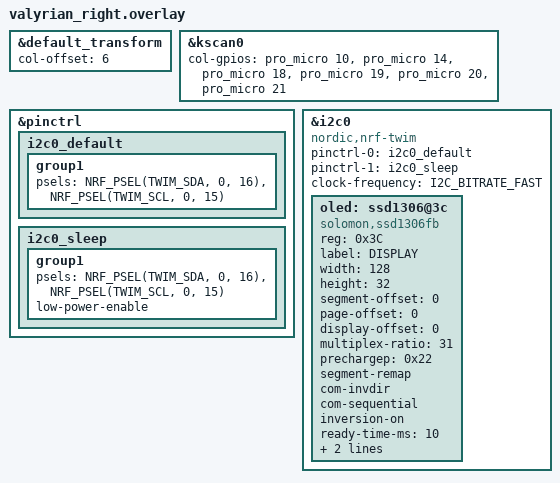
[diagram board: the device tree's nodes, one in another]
#include "valyrian.dtsi" 

&default_transform {
    col-offset = <6>;
};

&kscan0 {
    col-gpios
        = <&pro_micro 10 GPIO_ACTIVE_HIGH>
        , <&pro_micro 14 GPIO_ACTIVE_HIGH>
        , <&pro_micro 18 GPIO_ACTIVE_HIGH>
        , <&pro_micro 19 GPIO_ACTIVE_HIGH>
        , <&pro_micro 20 GPIO_ACTIVE_HIGH>
        , <&pro_micro 21 GPIO_ACTIVE_HIGH>
        ;
};

&pinctrl {
    /* configuration for i2c0 device, default state */
    i2c0_default: i2c0_default {
        group1 {
            psels = <NRF_PSEL(TWIM_SDA, 0, 16)>,
                <NRF_PSEL(TWIM_SCL, 0, 15)>;
        };
    };

    i2c0_sleep: i2c0_sleep {
        group1 {
            psels = <NRF_PSEL(TWIM_SDA, 0, 16)>,
                <NRF_PSEL(TWIM_SCL, 0, 15)>;
            low-power-enable;
        };
    };
};

&i2c0 {
    compatible = "nordic,nrf-twim"; // I2C controller instead of generic
    status = "okay";
    pinctrl-0 = <&i2c0_default>;
    pinctrl-1 = <&i2c0_sleep>;
    pinctrl-names = "default", "sleep";
    clock-frequency = <I2C_BITRATE_FAST>;
    oled: ssd1306@3c {
        compatible = "solomon,ssd1306fb";
        reg = <0x3C>;
        label = "DISPLAY";

        width = <128>;
        height = <32>;

        /* Required by the SSD1306 binding */
        segment-offset = <0>;
        page-offset = <0>;
        display-offset = <0>;
        multiplex-ratio = <31>;
        prechargep = <0x22>;

        /* Optional but commonly used properties */
        segment-remap;
        com-invdir;
        com-sequential;
        inversion-on;
        ready-time-ms = <10>;

        com-pins = <0x02>;

        /* Remove or uncomment if your panel has a reset GPIO */
        /* reset-gpios = <&gpio0 29 GPIO_ACTIVE_LOW>; */

        /* Keep reference to the bus (harmless if nested under &i2c0) */
        i2c-bus = <&i2c0>;
    };

    /* Nodes using the bus go here */
};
